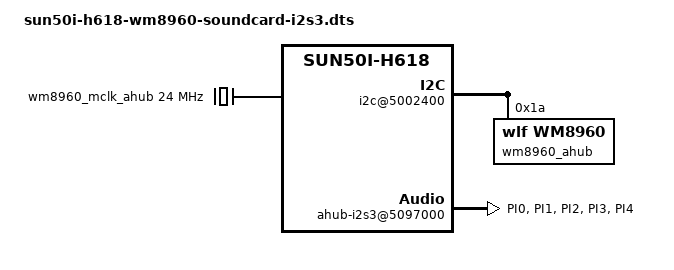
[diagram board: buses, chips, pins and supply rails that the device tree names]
/*
 * Device Tree Overlay for WM8960 Audio Codec (ReSpeaker 2-Mic HAT / Keyestudio)
 * on Orange Pi Zero 2W (Allwinner H618) - AHUB I2S3 version
 *
 * Copyright (C) 2025
 * License: MIT
 *
 * This is an alternative overlay that uses AHUB I2S3 instead of I2S2.
 * Try this if the primary overlay doesn't work.
 *
 * IMPORTANT: Requires i2c1-pi overlay for I2C on pins 3/5!
 *   In /boot/armbianEnv.txt:
 *     overlays=i2c1-pi sun50i-h618-wm8960-soundcard-i2s3
 *
 * GPIO Pin Mapping (40-pin header):
 *   Pin 3  (PI8)  - I2C SDA 
 *   Pin 5  (PI7)  - I2C SCL
 *   Pin 12 (PI1)  - I2S BCLK
 *   Pin 35 (PI2)  - I2S LRCK
 *   Pin 38 (PI4)  - I2S DIN (ADC - mic input)
 *   Pin 40 (PI3)  - I2S DOUT (DAC - speaker output)
 */

/dts-v1/;
/plugin/;

/ {
	compatible = "xunlong,orangepi-zero2w", "allwinner,sun50i-h618";

	/* Fragment 0: Add fixed MCLK clock */
	fragment@0 {
		target-path = "/";
		__overlay__ {
			wm8960_mclk_ahub: wm8960-mclk-ahub {
				compatible = "fixed-clock";
				#clock-cells = <0>;
				clock-frequency = <24000000>;
				clock-output-names = "wm8960-mclk";
			};
		};
	};

	/* Fragment 1: Add WM8960 codec to I2C1 */
	fragment@1 {
		target-path = "/soc/i2c@5002400";
		__overlay__ {
			#address-cells = <1>;
			#size-cells = <0>;
			status = "okay";

			wm8960_ahub: wm8960@1a {
				compatible = "wlf,wm8960";
				reg = <0x1a>;
				#sound-dai-cells = <0>;
				wlf,shared-lrclk;
				clocks = <&wm8960_mclk_ahub>;
				clock-names = "mclk";
			};
		};
	};

	/* Fragment 2: Define I2S/AHUB pins - use i2s3 functions */
	fragment@2 {
		target-path = "/soc/pinctrl@300b000";
		__overlay__ {
			ahub_daudio0_pins_a: ahub_daudio0@0 {
				pins = "PI0", "PI1", "PI2";
				function = "i2s3";
				drive-strength = <20>;
				bias-disable;
			};
			ahub_daudio0_pins_b: ahub_daudio0@1 {
				pins = "PI3";
				function = "i2s3_dout0";
				drive-strength = <20>;
				bias-disable;
			};
			ahub_daudio0_pins_c: ahub_daudio0@2 {
				pins = "PI4";
				function = "i2s3_din0";
				drive-strength = <20>;
				bias-disable;
			};
		};
	};

	/* Fragment 3: Create sound card using simple-audio-card */
	fragment@3 {
		target-path = "/";
		__overlay__ {
			wm8960_sound_ahub: wm8960-sound-ahub {
				compatible = "simple-audio-card";
				simple-audio-card,name = "wm8960-soundcard";
				simple-audio-card,format = "i2s";
				simple-audio-card,mclk-fs = <256>;
				simple-audio-card,bitclock-master = <&ahub_codec>;
				simple-audio-card,frame-master = <&ahub_codec>;
				status = "okay";

				simple-audio-card,widgets =
					"Microphone", "Mic Jack",
					"Line", "Line In",
					"Line", "Line Out",
					"Speaker", "Speaker",
					"Headphone", "Headphone Jack";

				simple-audio-card,routing =
					"Headphone Jack", "HP_L",
					"Headphone Jack", "HP_R",
					"Speaker", "SPK_LP",
					"Speaker", "SPK_LN",
					"Speaker", "SPK_RP",
					"Speaker", "SPK_RN",
					"LINPUT1", "Mic Jack",
					"LINPUT3", "Mic Jack",
					"RINPUT1", "Mic Jack",
					"RINPUT2", "Line In",
					"LINPUT2", "Line In";

				simple-audio-card,cpu {
					sound-dai = <&ahub_i2s3>;
				};

				ahub_codec: simple-audio-card,codec {
					sound-dai = <&wm8960_ahub>;
				};
			};
		};
	};

	/* Fragment 4: Enable AHUB I2S3 for audio */
	fragment@4 {
		target-path = "/soc/ahub-i2s3@5097000";
		__overlay__ {
			#sound-dai-cells = <0>;
			status = "okay";
			pinctrl-names = "default";
			pinctrl-0 = <&ahub_daudio0_pins_a>, <&ahub_daudio0_pins_b>, <&ahub_daudio0_pins_c>;
		};
	};
};
